# K1921VG1T register map
Vendor: NIIET; Series: K1921VGx; File version: 2.8
CPU: other r0p1, little endian, MPU, FPU, 4 interrupt priority bits
Registers are 32-bit, read-write, reset 0x0 unless marked. A register's access mark holds for its fields unless they carry their own. Offsets are from the block's base; [hi:lo] are bit positions; lines under a group give offsets from that group; {n}, {i} and the like mark numbered series.

## LIN0 — LIN control registers
Base 0x52000000
Same registers: LIN1 0x52001000, LIN2 0x52002000, LIN3 0x52003000, LIN4 0x52004000, LIN5 0x52005000, LIN6 0x52006000, LIN7 0x52007000
{0x0+4i} DTX[{i}] (i=0..7) group
  0x00 VALUE — Transmitted data register
    [7:0] TXD — Transmitted data
{0x20+4i} DRX[{i}] (i=0..7) group
  0x00 VALUE — Received data register
    [7:0] RXD — Received data
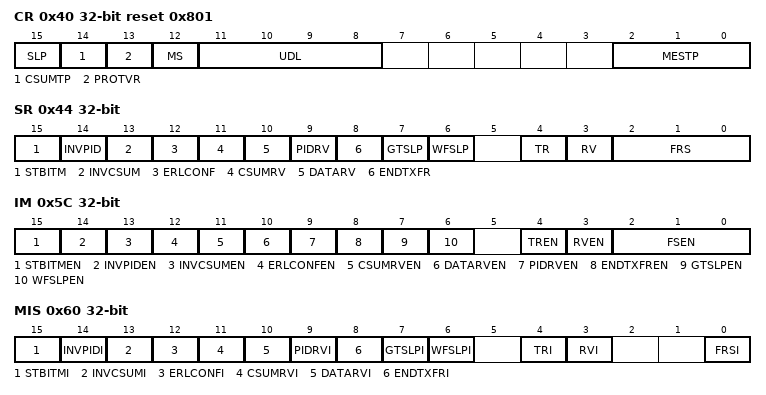
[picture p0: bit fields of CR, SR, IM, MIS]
0x40 CR reset 0x801 — Control register
  [15] SLP — Sleep state bit
  [14] CSUMTP — Checksum type bit
  [13] PROTVR — Protocol type bit
  [12] MS — Device type bit master/slave
  [11:8] UDL — Number of data fields in one message frame
  [2:0] MESTP — Message frame type
    1=IDLE (IDLE state (only in transmit mode)); 2=HEADER (HEADER state); 3=HEADER_RESPONSE (HEADER+RESPONSE state); 4=RESPONSE_RESEIVE (RESPONSE RESEIVE state); 5=RESPONSE_TRANSMIT (RESPONSE TRANSMIT state); 7=SEND_WAKE (send a signal WAKE)
0x44 SR — Status register
  [15] STBITM — No stop symbol bit
  [14] INVPID — PID error bit
  [13] INVCSUM — Checksum error bit
  [12] ERLCONF — Line conflict bit
  [11] CSUMRV — Checksum received bit
  [10] DATARV — Data received bit
  [9] PIDRV — PID received bit
  [8] ENDTXFR — End of transmission bit
  [7] GTSLP — Received message frame is a sleep signal
  [6] WFSLP — During sleep, a wake-up signal is received
  [4] TR ro — The activity bit of the transmitting part of the interface
  [3] RV ro — The activity bit of the receiving part of the interface
  [2:0] FRS ro — Current state of the device
    1=IDLE (IDLE state (only in transmit mode)); 2=BREAK (BREAK state); 3=SYNC (SYNC state); 4=PID (PID state); 5=DATA (DATA state); 6=CSUM (CSUM state); 7=SEND_WAKE (send a signal WAKE state)
0x48 BL reset 0x1E7 — Register for setting the length of the BREAK field
  [15:0] BRKLEN — Minimum length of the synchronization break field
0x4C SRR reset 0x12C — Transfer rate setting register
  [15:0] SPDR — Transmission rate of the main device
0x50 PTX — Register of the PID being sent
  [5:0] PIDTX — PID is sent in the next data frame
0x54 PRX ro — Register of the received PID
  [5:0] PIDRX — Value of the received PID
0x58 CSRX ro — Register of the received checksum
  [7:0] CSUMRX — Value of the accepted checksum
0x5C IM — Mask interrupt register
  [15] STBITMEN — Enable interrupt by the failure of a stop bit
  [14] INVPIDEN — Enable interrupt to receive a PID with broken parity
  [13] INVCSUMEN — Enable interrupt to receive an incorrect checksum
  [12] ERLCONFEN — Enable interrupt when a line conflict occurs
  [11] CSUMRVEN — Enable interrupt by receiving of the checksum field
  [10] DATARVEN — Enable interrupt by receiving a data field
  [9] PIDRVEN — Enable interrupt by receiving the PID field
  [8] ENDTXFREN — Enable interrupt when the transmission of the next message frame is completed
  [7] GTSLPEN — Enable interrupt when receiving a sleep signal
  [6] WFSLPEN — Enable interrupt when receiving a wake-up signal
  [4] TREN — Enable interrupt by activating the transmitting part of the device
  [3] RVEN — Enable interrupt by activating the receiving part of the device
  [2:0] FSEN — Enable interrupt when message frame field set
0x60 MIS — Masked interrupt status register
  [15] STBITMI, [14] INVPIDI, [13] INVCSUMI, [12] ERLCONFI, [11] CSUMRVI, [10] DATARVI, [9] PIDRVI, [8] ENDTXFRI, [7] GTSLPI, [6] WFSLPI, [4] TRI, [3] RVI, [0] FRSI

## SPI0 — SPI control registers
Base 0x52008000
Same registers: SPI1 0x52009000, SPI2 0x5200A000, SPI3 0x5200B000, SPI4 0x5200C000, SPI5 0x5200D000, SPI6 0x5200E000, SPI7 0x5200F000
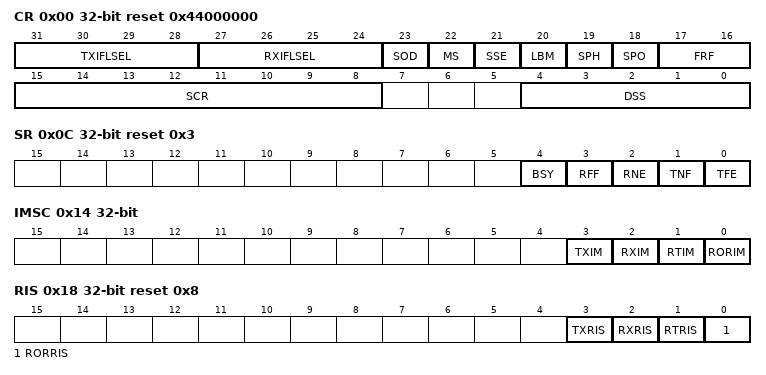
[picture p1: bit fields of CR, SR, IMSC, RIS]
0x00 CR reset 0x44000000 — Control register
  [31:28] TXIFLSEL — Transmit interrupt FIFO level select
  [27:24] RXIFLSEL — Receive interrupt FIFO level select
  [23] SOD — Disable bit data
  [22] MS — Select mode
  [21] SSE — Enable transceiver
  [20] LBM — Test loopback mode
  [19] SPH — Phase SSPCLKOUT
  [18] SPO — Polarity SSPCLKOUT
  [17:16] FRF — Select protocol
    0=SPI (SPI of Motorola); 1=SSI (SSI of Texas Instruments); 2=Microwire of National Semiconductor
  [15:8] SCR — Value divider
  [4:0] DSS — Size of data is (value + 1) bits
    {v}={v+1}bit (data size {v+1} bits) (v=3..31)
0x08 DR — Data register
  [31:0] DATA
0x0C SR ro reset 0x3 — State register
  [4] BSY — Activity flag
  [3] RFF — Indicate full receive buffer
  [2] RNE — Indicate not empty receive buffer
  [1] TNF — Indicator the transmitter FIFO buffer is not full
  [0] TFE — FIFO buffer empty flag transmitter
0x10 CPSR — Clock division factor register
  [7:0] CPSDVSR — Clock division factor. Bit0 always 0
0x14 IMSC — Mask interrupt register
  [3] TXIM — SSPTXINTR interrupt mask bit to fill 50% or less of the FIFO buffer of the transmitter
  [2] RXIM — SSPRXINTR interrupt mask bit to fill 50% or less of the receiver FIFO buffer
  [1] RTIM — Interrupt mask bit SSPRTINTR timeout receiver
  [0] RORIM — Interrupt mask bit SSPRORINTR buffer overflow receiver
0x18 RIS ro reset 0x8 — Status register interrupt without mask
  [3] TXRIS — Interrupt status before masking SSPTXINTR
  [2] RXRIS — Interrupt status before masking SSPRXINTR
  [1] RTRIS — Interrupt status before masking SSPRTINTR
  [0] RORRIS — Interrupt status before masking SSPRORINTR
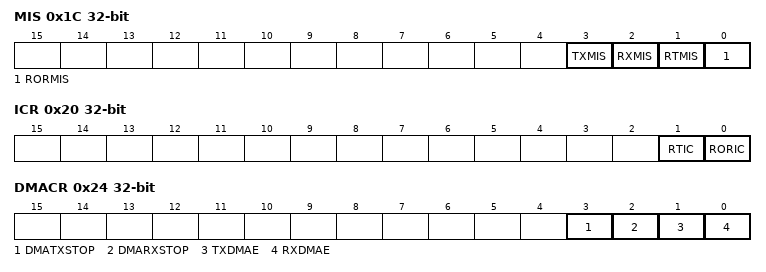
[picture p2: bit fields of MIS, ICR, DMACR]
0x1C MIS ro — Status register interrupt masking account
  [3] TXMIS — Masked interrupt status SSPTXINTR
  [2] RXMIS — Masked interrupt status SSPRXINTR
  [1] RTMIS — Masked interrupt status SSPRTINTR
  [0] RORMIS — Masked interrupt status SSPRORINTR
0x20 ICR wo — Register reset interrupt
  [1] RTIC — Reset interrupt SSPRTINTR
  [0] RORIC — Reset interrupt SSPRORINTR
0x24 DMACR — Control register DMA
  [3] DMATXSTOP — Automatic clear DMA TX request generation when channel ends all transactions
  [2] DMARXSTOP — Automatic clear DMA RX request generation when channel ends all transactions
  [1] TXDMAE — DMA enable bit transmission
  [0] RXDMAE — DMA enable bit at reception
